# CY8C5568AXI_060 register map
File version: 0.1
CY8C55
Registers are 8-bit, read-write, no defined reset value unless marked. A register's access mark holds for its fields unless they carry their own. Offsets are from the block's base; lines under a group give offsets from that group; [hi:lo] are bit positions; {n}, {i} and the like mark numbered series; 'fields as' and 'values as' point back to an identical list; <NAME> marks a mode.

## Memory map
0x4000642D PlayerBT1 size 0x41 — UART

## PlayerBT1 — UART
Base 0x4000642D
0x00 RX_PlayerBT1_RX_ADDRESS1 — RX Address1 Register
0x10 RX_PlayerBT1_RX_ADDRESS2 — RX Address2 Register
0x1D TX_PlayerBT1_TX_DATA — TX Data Register
0x20 RX_PlayerBT1_RX_DATA — RX Data Register
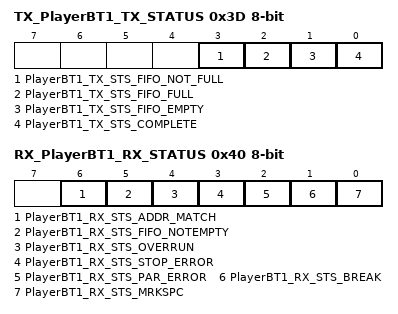
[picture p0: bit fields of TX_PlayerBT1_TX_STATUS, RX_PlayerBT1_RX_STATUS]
0x3D TX_PlayerBT1_TX_STATUS — TX status register
  [3] PlayerBT1_TX_STS_FIFO_NOT_FULL ro, [2] PlayerBT1_TX_STS_FIFO_FULL ro, [1] PlayerBT1_TX_STS_FIFO_EMPTY ro, [0] PlayerBT1_TX_STS_COMPLETE ro
0x40 RX_PlayerBT1_RX_STATUS — RX status register
  [6] PlayerBT1_RX_STS_ADDR_MATCH ro, [5] PlayerBT1_RX_STS_FIFO_NOTEMPTY ro, [4] PlayerBT1_RX_STS_OVERRUN ro, [3] PlayerBT1_RX_STS_STOP_ERROR ro, [2] PlayerBT1_RX_STS_PAR_ERROR ro, [1] PlayerBT1_RX_STS_BREAK ro, [0] PlayerBT1_RX_STS_MRKSPC ro
